# PIC32MZ1024EFM064 register map
Vendor: Microchip
Registers are 32-bit, read-write, reset 0x0 unless marked. A register's access mark holds for its fields unless they carry their own. Addresses are absolute, and some are shared; only a register's first bit layout is shown; [hi:lo] are bit positions; {n}, {i} and the like mark numbered series; 'fields as' and 'values as' point back to an identical list.

## CRYPTO
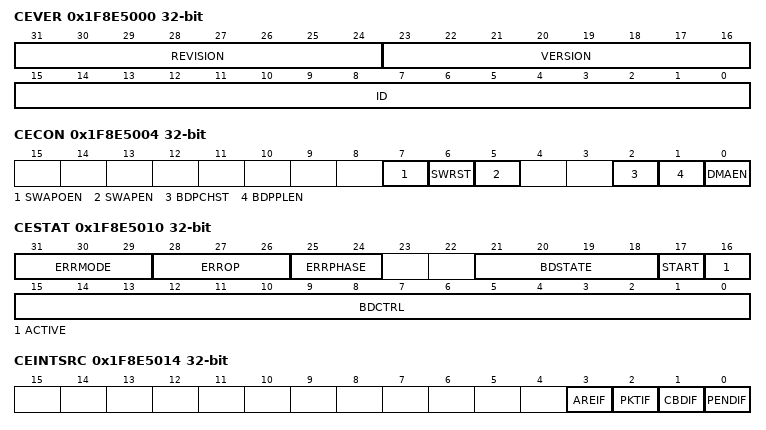
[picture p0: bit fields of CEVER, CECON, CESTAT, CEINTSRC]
0x1F8E5000 CEVER ro reset not defined — (power-on value xxxxxxxxxxxxxxxxxxxxxxxxxxxxxxxx)
  [31:24] REVISION, [23:16] VERSION, [15:0] ID
0x1F8E5004 CECON
  [7] SWAPOEN, [6] SWRST, [5] SWAPEN, [2] BDPCHST, [1] BDPPLEN, [0] DMAEN
0x1F8E5008 CEBDADDR ro
  [31:0] BDPADDR
0x1F8E500C CEBDPADDR ro
  [31:0] BASEADDR
0x1F8E5010 CESTAT ro
  [31:29] ERRMODE, [28:26] ERROP, [25:24] ERRPHASE, [21:18] BDSTATE, [17] START, [16] ACTIVE, [15:0] BDCTRL
0x1F8E5014 CEINTSRC ro
  [3] AREIF, [2] PKTIF, [1] CBDIF, [0] PENDIF
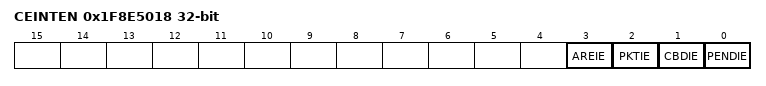
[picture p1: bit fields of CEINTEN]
0x1F8E5018 CEINTEN
  [3] AREIE, [2] PKTIE, [1] CBDIE, [0] PENDIE
0x1F8E501C CEPOLLCON
  [15:0] BDPPLCON
0x1F8E5020 CEHDLEN
  [7:0] HDRLEN
0x1F8E5024 CETRLLEN
  [7:0] TRLRLEN

## RNG
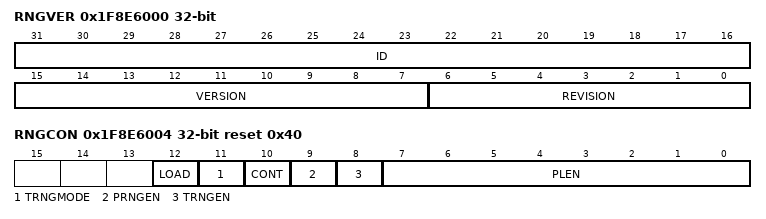
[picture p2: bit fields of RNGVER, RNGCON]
0x1F8E6000 RNGVER ro
  [31:16] ID, [15:7] VERSION, [6:0] REVISION
0x1F8E6004 RNGCON reset 0x40
  [12] LOAD, [11] TRNGMODE, [10] CONT, [9] PRNGEN, [8] TRNGEN, [7:0] PLEN
0x1F8E6008 RNGPOLY1 reset 0xFFFF0000
  [31:0] POLY
0x1F8E600C RNGPOLY2 reset 0xFFFF0000
  [31:0] POLY
0x1F8E6010 RNGNUMGEN1 reset 0xFFFFFFFF
  [31:0] RNG
0x1F8E6014 RNGNUMGEN2 reset 0xFFFFFFFF
  [31:0] RNG
0x1F8E6018 RNGSEED1 ro
  [31:0] SEED
0x1F8E601C RNGSEED2 ro
  [31:0] SEED
0x1F8E6020 RNGCNT
  [6:0] RCNT

## SB
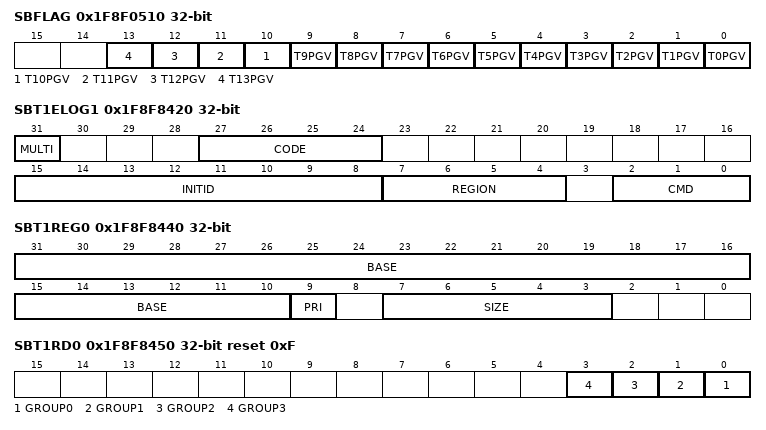
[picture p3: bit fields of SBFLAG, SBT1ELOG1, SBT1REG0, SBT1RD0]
0x1F8F0510 SBFLAG ro
  [n] T{n}PGV (n=0..13)
0x1F8F8420 SBT1ELOG1
  [31] MULTI, [27:24] CODE, [15:8] INITID ro, [7:4] REGION ro, [2:0] CMD ro
0x1F8F8424 SBT1ELOG2 ro
  [1:0] GROUP
0x1F8F8428 SBT1ECON
  [24] ERRP
0x1F8F8430 SBT1ECLRS ro
  [0] CLEAR
0x1F8F8438 SBT1ECLRM ro
  [0] CLEAR
0x1F8F8440 SBT1REG0 reset not defined — (power-on value 0000000000000000000000x-00000---)
  [31:10] BASE, [9] PRI ro, [7:3] SIZE
0x1F8F8450 SBT1RD0 reset 0xF
  [n] GROUP{n} (n=0..3)
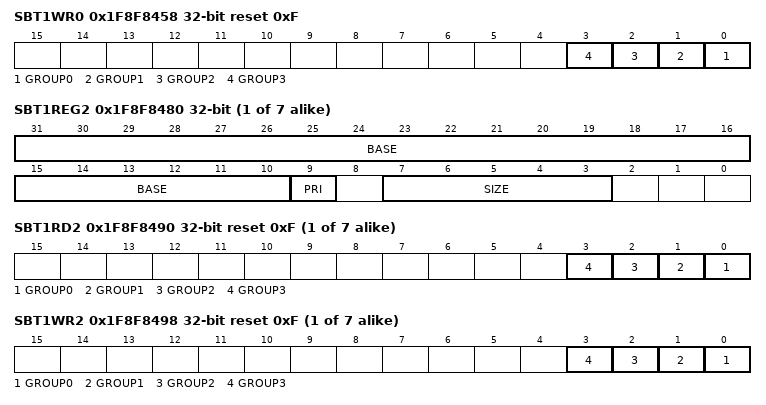
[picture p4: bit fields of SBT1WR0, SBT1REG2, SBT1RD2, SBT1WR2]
0x1F8F8458 SBT1WR0 reset 0xF
  [n] GROUP{n} (n=0..3)
{0x1F8F8440+0x20*i} SBT1REG{i} reset not defined (i=2..8) — (power-on value 0000000000000000000000x-00000---)
  [31:10] BASE, [9] PRI ro, [7:3] SIZE
{0x1F8F8450+0x20*i} SBT1RD{i} reset 0xF (i=2..8)
  [n] GROUP{n} (n=0..3)
{0x1F8F8458+0x20*i} SBT1WR{i} reset 0xF (i=2..8)
  [n] GROUP{n} (n=0..3)

## DOS_EIP_00136_ssx
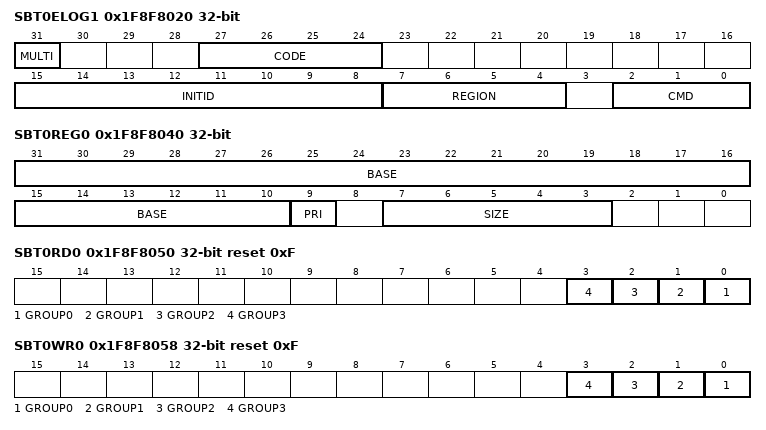
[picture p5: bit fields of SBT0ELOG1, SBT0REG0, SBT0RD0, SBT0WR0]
0x1F8F8020 SBT0ELOG1
  [31] MULTI, [27:24] CODE, [15:8] INITID ro, [7:4] REGION ro, [2:0] CMD ro
0x1F8F8024 SBT0ELOG2 ro
  [1:0] GROUP
0x1F8F8028 SBT0ECON
  [24] ERRP
0x1F8F8030 SBT0ECLRS ro
  [0] CLEAR
0x1F8F8038 SBT0ECLRM ro
  [0] CLEAR
0x1F8F8040 SBT0REG0 reset not defined — (power-on value 0000000000000000000000x-00000---)
  [31:10] BASE, [9] PRI ro, [7:3] SIZE
0x1F8F8050 SBT0RD0 reset 0xF
  [n] GROUP{n} (n=0..3)
0x1F8F8058 SBT0WR0 reset 0xF
  [n] GROUP{n} (n=0..3)
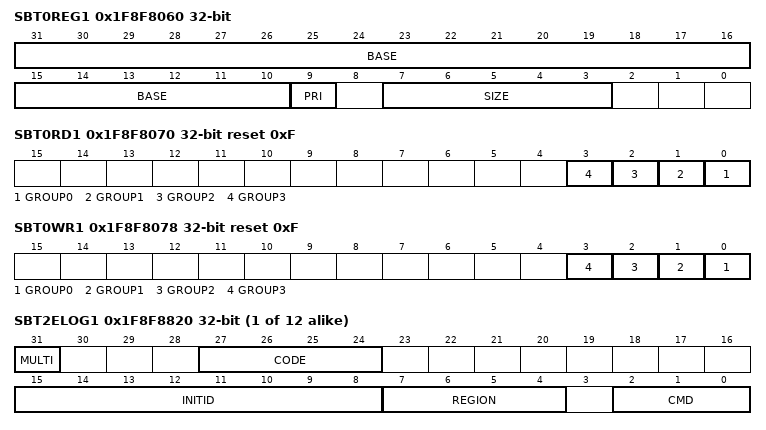
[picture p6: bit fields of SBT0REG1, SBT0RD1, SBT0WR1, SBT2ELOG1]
0x1F8F8060 SBT0REG1 reset not defined — (power-on value 0000000000000000000000x-00000---)
  [31:10] BASE, [9] PRI ro, [7:3] SIZE
0x1F8F8070 SBT0RD1 reset 0xF
  [n] GROUP{n} (n=0..3)
0x1F8F8078 SBT0WR1 reset 0xF
  [n] GROUP{n} (n=0..3)
{0x1F8F8020+0x400*i} SBT{i}ELOG1 (i=2..13)
  fields as SBT0ELOG1
{0x1F8F8024+0x400*i} SBT{i}ELOG2 ro (i=2..13)
  [1:0] GROUP
{0x1F8F8028+0x400*i} SBT{i}ECON (i=2..13)
  [24] ERRP
{0x1F8F8030+0x400*i} SBT{i}ECLRS ro (i=2..13)
  [0] CLEAR
{0x1F8F8038+0x400*i} SBT{i}ECLRM ro (i=2..13)
  [0] CLEAR
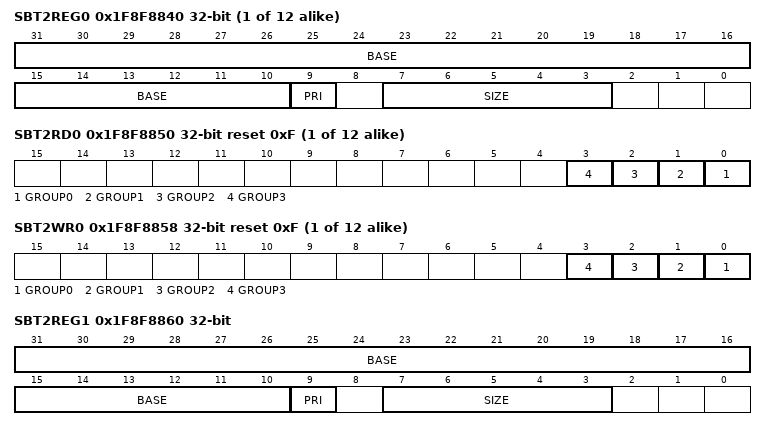
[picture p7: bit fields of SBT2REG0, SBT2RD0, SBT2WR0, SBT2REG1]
{0x1F8F8040+0x400*i} SBT{i}REG0 reset not defined (i=2..13) — (power-on value 0000000000000000000000x-00000---)
  [31:10] BASE, [9] PRI ro, [7:3] SIZE
{0x1F8F8050+0x400*i} SBT{i}RD0 reset 0xF (i=2..13)
  [n] GROUP{n} (n=0..3)
{0x1F8F8058+0x400*i} SBT{i}WR0 reset 0xF (i=2..13)
  [n] GROUP{n} (n=0..3)
0x1F8F8860 SBT2REG1 reset not defined — (power-on value 0000000000000000000000x-00000---)
  [31:10] BASE, [9] PRI ro, [7:3] SIZE
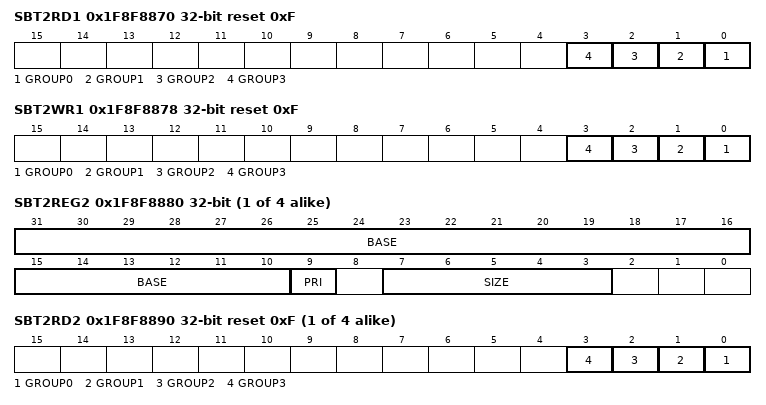
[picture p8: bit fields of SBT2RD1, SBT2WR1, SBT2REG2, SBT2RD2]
0x1F8F8870 SBT2RD1 reset 0xF
  [n] GROUP{n} (n=0..3)
0x1F8F8878 SBT2WR1 reset 0xF
  [n] GROUP{n} (n=0..3)
{0x1F8F8080+0x400*i} SBT{i}REG2 reset not defined (i=2..5) — (power-on value 0000000000000000000000x-00000---)
  [31:10] BASE, [9] PRI ro, [7:3] SIZE
{0x1F8F8090+0x400*i} SBT{i}RD2 reset 0xF (i=2..5)
  [n] GROUP{n} (n=0..3)
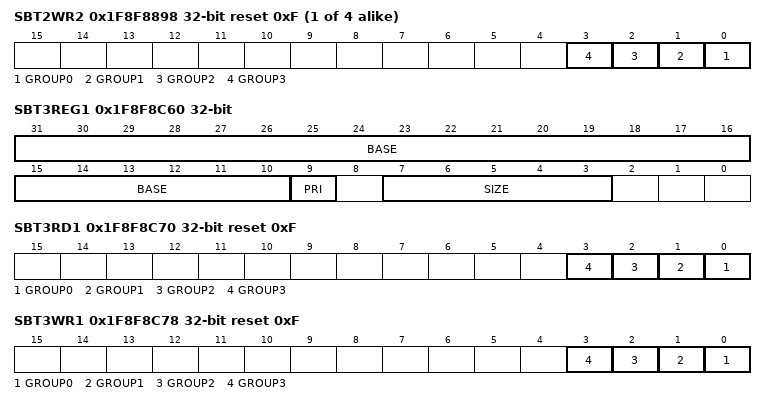
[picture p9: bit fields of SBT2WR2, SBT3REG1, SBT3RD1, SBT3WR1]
{0x1F8F8098+0x400*i} SBT{i}WR2 reset 0xF (i=2..5)
  [n] GROUP{n} (n=0..3)
0x1F8F8C60 SBT3REG1 reset not defined — (power-on value 0000000000000000000000x-00000---)
  [31:10] BASE, [9] PRI ro, [7:3] SIZE
0x1F8F8C70 SBT3RD1 reset 0xF
  [n] GROUP{n} (n=0..3)
0x1F8F8C78 SBT3WR1 reset 0xF
  [n] GROUP{n} (n=0..3)
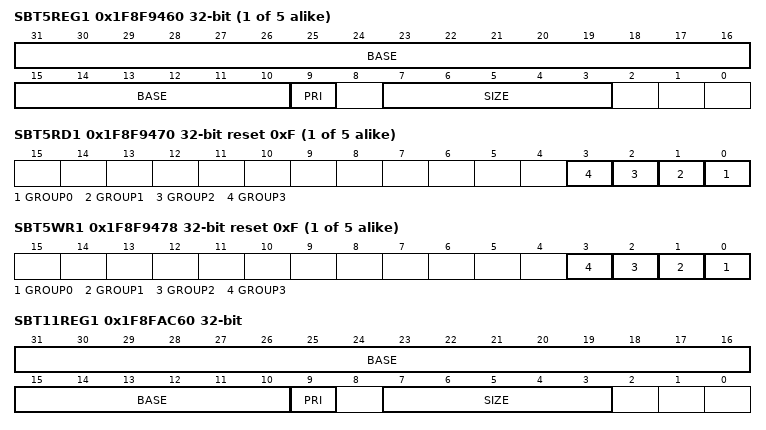
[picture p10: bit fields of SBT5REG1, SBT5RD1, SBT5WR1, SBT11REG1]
{0x1F8F8060+0x400*i} SBT{i}REG1 reset not defined (i=5..9) — (power-on value 0000000000000000000000x-00000---)
  [31:10] BASE, [9] PRI ro, [7:3] SIZE
{0x1F8F8070+0x400*i} SBT{i}RD1 reset 0xF (i=5..9)
  [n] GROUP{n} (n=0..3)
{0x1F8F8078+0x400*i} SBT{i}WR1 reset 0xF (i=5..9)
  [n] GROUP{n} (n=0..3)
0x1F8FAC60 SBT11REG1 reset not defined — (power-on value 0000000000000000000000x-00000---)
  [31:10] BASE, [9] PRI ro, [7:3] SIZE
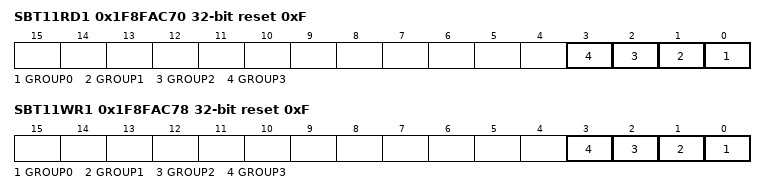
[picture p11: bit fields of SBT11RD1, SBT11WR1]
0x1F8FAC70 SBT11RD1 reset 0xF
  [n] GROUP{n} (n=0..3)
0x1F8FAC78 SBT11WR1 reset 0xF
  [n] GROUP{n} (n=0..3)
